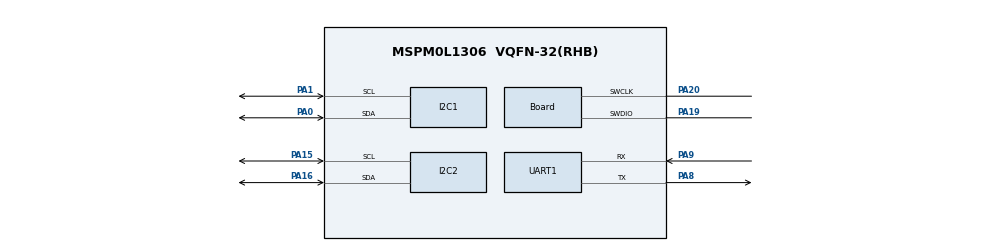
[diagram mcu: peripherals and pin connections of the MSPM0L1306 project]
//@cliArgs --device "MSPM0L130X" --package "VQFN-32(RHB)" --part "Default"
//@v2CliArgs --device "MSPM0L1306" --package "VQFN-32(RHB)"
// @cliArgs --board /ti/boards/LP_MSPM0L1306 --rtos nortos

/**
 * Import the modules used in this configuration.
 */
const I2C           = scripting.addModule("/ti/driverlib/I2C", {}, false);
const I2C1          = I2C.addInstance();
const I2C2          = I2C.addInstance();
const SYSCTL        = scripting.addModule("/ti/driverlib/SYSCTL");
const UART          = scripting.addModule("/ti/driverlib/UART", {}, false);
const UART1         = UART.addInstance();
const ProjectConfig = scripting.addModule("/ti/project_config/ProjectConfig");

/**
 * Write custom configuration values to the imported modules.
 */
I2C1.basicEnableController             = true;
I2C1.basicTargetSecAddressEnable       = true;
I2C1.enableDMAEvent1                   = false;
I2C1.enableDMAEvent2                   = false;
I2C1.advAnalogGlitchFilter             = "DISABLED";
I2C1.advControllerTXFIFOTRIG           = "BYTES_1";
I2C1.intController                     = ["NACK","RXFIFO_TRIGGER","RX_DONE","TX_DONE"];
I2C1.$name                             = "I2C_BRIDGE";
I2C1.peripheral.$assign                = "I2C0";
I2C1.peripheral.sdaPin.$assign         = "PA0";
I2C1.peripheral.sclPin.$assign         = "PA1";

const Board                       = scripting.addModule("/ti/driverlib/Board", {}, false);
Board.peripheral.$assign          = "DEBUGSS";
Board.peripheral.swclkPin.$assign = "PA20";
Board.peripheral.swdioPin.$assign = "PA19";

I2C2.$name                             = "I2C_BRIDGE2";
I2C2.basicEnableController             = true;
I2C2.intController                     = ["NACK","RXFIFO_TRIGGER","RX_DONE","TX_DONE"];
I2C2.advAnalogGlitchFilter             = "DISABLED";
I2C2.advControllerTXFIFOTRIG           = "BYTES_1";
I2C2.peripheral.$assign                = "I2C1";
I2C2.peripheral.sdaPin.$assign         = "PA16";
I2C2.peripheral.sclPin.$assign         = "PA15";
SYSCTL.clockTreeEn = true;

UART1.rxFifoThreshold                  = "DL_UART_RX_FIFO_LEVEL_ONE_ENTRY";
UART1.enableDMARX                      = false;
UART1.enableDMATX                      = false;
UART1.enabledInterrupts                = ["RX"];
UART1.$name                            = "UART_BRIDGE";
UART1.peripheral.$assign               = "UART0";
UART1.peripheral.rxPin.$assign         = "PA9";
UART1.peripheral.txPin.$assign         = "PA8";

ProjectConfig.deviceSpin = "MSPM0L1306";
scripting.suppress("Migrating requires going through the Switch Board or Device menu in the Device View section\\.", ProjectConfig, "deviceSpin");
